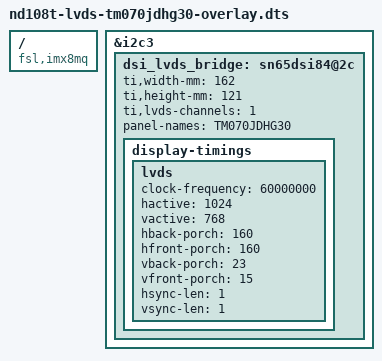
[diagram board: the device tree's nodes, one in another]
/*
 * Copyright 2017 NXP
 *
 * This program is free software; you can redistribute it and/or
 * modify it under the terms of the GNU General Public License
 * as published by the Free Software Foundation; either version 2
 * of the License, or (at your option) any later version.
 *
 * This program is distributed in the hope that it will be useful,
 * but WITHOUT ANY WARRANTY; without even the implied warranty of
 * MERCHANTABILITY or FITNESS FOR A PARTICULAR PURPOSE.  See the
 * GNU General Public License for more details.
 */

/dts-v1/;
/plugin/;

/ {
	compatible = "fsl,imx8mq";

	fragment@0 {
		target = <&i2c3>;
		__overlay__ {
			dsi_lvds_bridge: sn65dsi84@2c {
                ti,width-mm = <162>;
                ti,height-mm = <121>;
                ti,lvds-channels = <1>;
                panel-names = "TM070JDHG30";

                display-timings {
                    lvds {
                        clock-frequency = <60000000>;
                        hactive = <1024>;
                        vactive = <768>;
                        hback-porch = <160>;
                        hfront-porch = <160>;
                        vback-porch = <23>;
                        vfront-porch = <15>;
                        hsync-len = <1>;
                        vsync-len = <1>;
                    };
                };
            };
		};
	};
};
